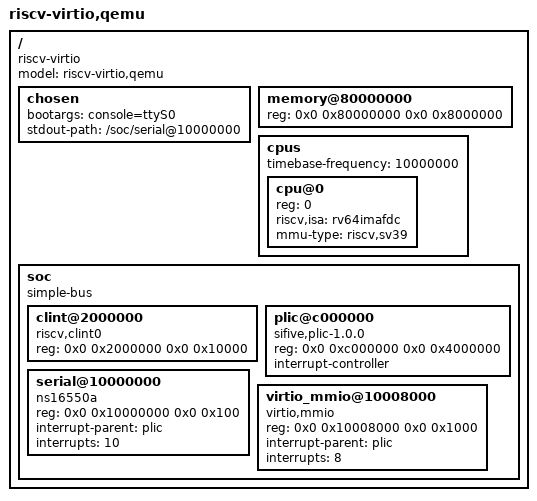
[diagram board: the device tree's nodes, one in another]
// FDT 解析器测试 fixture（结构参照 QEMU virt 自动生成的 DTB）。
// 运行时 DTB 由 QEMU 经 a1 传入，本文件不参与引导 —— 仅用于 fdt/ 的 host test。
/dts-v1/;

/ {
    #address-cells = <2>;
    #size-cells = <2>;
    compatible = "riscv-virtio";
    model = "riscv-virtio,qemu";

    chosen {
        bootargs = "console=ttyS0";
        stdout-path = "/soc/serial@10000000";
    };

    memory@80000000 {
        device_type = "memory";
        reg = <0x0 0x80000000 0x0 0x8000000>;
    };

    cpus {
        #address-cells = <1>;
        #size-cells = <0>;
        timebase-frequency = <10000000>;

        cpu@0 {
            device_type = "cpu";
            reg = <0>;
            status = "okay";
            riscv,isa = "rv64imafdc";
            mmu-type = "riscv,sv39";
        };
    };

    soc {
        #address-cells = <2>;
        #size-cells = <2>;
        compatible = "simple-bus";
        ranges;

        clint@2000000 {
            compatible = "riscv,clint0";
            reg = <0x0 0x2000000 0x0 0x10000>;
        };

        plic@c000000 {
            compatible = "sifive,plic-1.0.0";
            reg = <0x0 0xc000000 0x0 0x4000000>;
            #interrupt-cells = <1>;
            interrupt-controller;
        };

        serial@10000000 {
            compatible = "ns16550a";
            reg = <0x0 0x10000000 0x0 0x100>;
            interrupt-parent = <&plic>;
            interrupts = <10>;
        };

        virtio_mmio@10008000 {
            compatible = "virtio,mmio";
            reg = <0x0 0x10008000 0x0 0x1000>;
            interrupt-parent = <&plic>;
            interrupts = <8>;
        };
    };
};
